VERSION "ODrive v0.5.6 CANSimple - generated by tools/gen_can_dbc.py on 2026-11-18"

NS_ :

BS_:

BU_: HOST ODrive

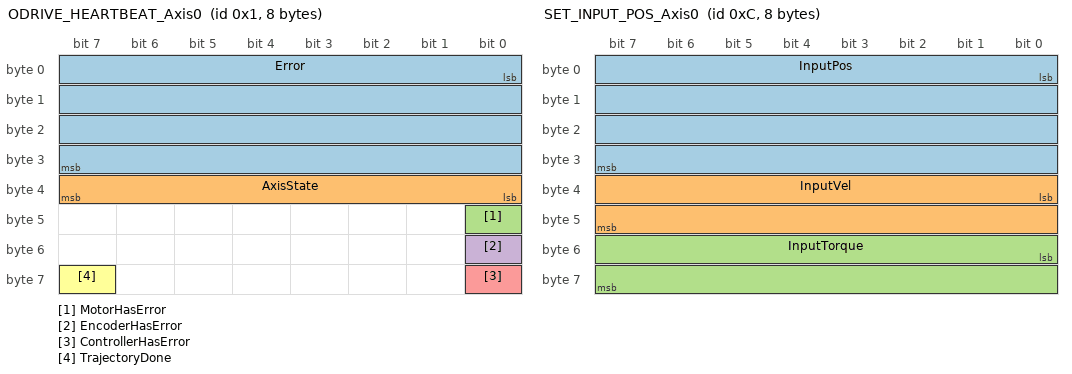
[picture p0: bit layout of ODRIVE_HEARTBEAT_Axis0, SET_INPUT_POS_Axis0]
BO_ 1 ODRIVE_HEARTBEAT_Axis0: 8 ODrive
 SG_ Error : 0|32@1+ (1,0) [0|0] "" HOST
 SG_ AxisState : 32|8@1+ (1,0) [0|0] "" HOST
 SG_ MotorHasError : 40|1@1+ (1,0) [0|0] "" HOST
 SG_ EncoderHasError : 48|1@1+ (1,0) [0|0] "" HOST
 SG_ ControllerHasError : 56|1@1+ (1,0) [0|0] "" HOST
 SG_ TrajectoryDone : 63|1@1+ (1,0) [0|0] "" HOST
CM_ BO_ 1 "Periodic heartbeat (config.can.heartbeat_rate_ms). See CANSimple::send_heartbeat().";
CM_ SG_ 1 Error "Axis::error_ bitfield, see odrive-interface.yaml Axis.Error";
CM_ SG_ 1 AxisState "axis.current_state_";
CM_ SG_ 1 MotorHasError "1 = motor error present";
CM_ SG_ 1 EncoderHasError "1 = encoder error present";
CM_ SG_ 1 ControllerHasError "1 = controller error present";
CM_ SG_ 1 TrajectoryDone "1 = trapezoidal trajectory finished";
VAL_ 1 AxisState 0 "UNDEFINED" 1 "IDLE" 2 "STARTUP_SEQUENCE" 3 "FULL_CALIBRATION_SEQUENCE" 4 "MOTOR_CALIBRATION" 6 "ENCODER_INDEX_SEARCH" 7 "ENCODER_OFFSET_CALIBRATION" 8 "CLOSED_LOOP_CONTROL" 9 "LOCKIN_SPIN" 10 "ENCODER_DIR_FIND" 11 "HOMING" 12 "ENCODER_HALL_POLARITY_CALIBRATION" 13 "ENCODER_HALL_PHASE_CALIBRATION" ;

BO_ 2 ODRIVE_ESTOP_Axis0: 0 HOST
CM_ BO_ 2 "Emergency stop: sets Axis::ERROR_ESTOP_REQUESTED. No payload.";

BO_ 3 GET_MOTOR_ERROR_Axis0: 8 ODrive
 SG_ MotorError : 0|64@1+ (1,0) [0|0] "" HOST
CM_ BO_ 3 "Response: motor error bitfield. Trigger: RTR frame or empty frame with same ID.";
CM_ SG_ 3 MotorError "motor.error_ bitfield (64 bit)";

BO_ 4 GET_ENCODER_ERROR_Axis0: 8 ODrive
 SG_ EncoderError : 0|32@1+ (1,0) [0|0] "" HOST
CM_ BO_ 4 "Response: encoder error. Trigger: RTR or empty frame with same ID.";
CM_ SG_ 4 EncoderError "encoder.error_ bitfield";

BO_ 5 GET_SENSORLESS_ERROR_Axis0: 8 ODrive
 SG_ SensorlessError : 0|32@1+ (1,0) [0|0] "" HOST
CM_ BO_ 5 "Response: sensorless estimator error. Trigger: RTR or empty frame with same ID.";
CM_ SG_ 5 SensorlessError "sensorless_estimator.error_ bitfield";

BO_ 6 SET_AXIS_NODE_ID_Axis0: 8 HOST
 SG_ NewNodeId : 0|32@1+ (1,0) [0|0] "" ODrive
CM_ BO_ 6 "Set a new CAN node id (takes effect immediately, not persisted).";
CM_ SG_ 6 NewNodeId "new axis.config_.can.node_id";

BO_ 7 SET_AXIS_REQUESTED_STATE_Axis0: 8 HOST
 SG_ RequestedState : 0|32@1- (1,0) [0|0] "" ODrive
CM_ BO_ 7 "Request a state machine transition (like odrivetool: axis.requested_state = ...).";
CM_ SG_ 7 RequestedState "see AxisState value table";

BO_ 8 SET_AXIS_STARTUP_CONFIG_Axis0: 8 HOST
CM_ BO_ 8 "Not implemented in firmware v0.5.6.";

BO_ 9 GET_ENCODER_ESTIMATES_Axis0: 8 ODrive
 SG_ PosEstimate : 0|32@1+ (1,0) [0|0] "turn" HOST
 SG_ VelEstimate : 32|32@1+ (1,0) [0|0] "turn/s" HOST
CM_ BO_ 9 "Periodic (config.can.encoder_rate_ms) or on request: position/velocity estimate.";
CM_ SG_ 9 PosEstimate "controller pos_estimate IEEE-754 float32, little-endian (decoded natively via SIG_VALTYPE_).";
CM_ SG_ 9 VelEstimate "controller vel_estimate IEEE-754 float32, little-endian (decoded natively via SIG_VALTYPE_).";
SIG_VALTYPE_ 9 PosEstimate : 1;
SIG_VALTYPE_ 9 VelEstimate : 1;

BO_ 10 GET_ENCODER_COUNT_Axis0: 8 ODrive
 SG_ ShadowCount : 0|32@1- (1,0) [0|0] "" HOST
 SG_ CountInCPR : 32|32@1- (1,0) [0|0] "" HOST
CM_ BO_ 10 "Raw encoder counts (on request).";
CM_ SG_ 10 ShadowCount "encoder.shadow_count_ (raw ticks)";
CM_ SG_ 10 CountInCPR "encoder.count_in_cpr_ (raw ticks)";

BO_ 11 SET_CONTROLLER_MODES_Axis0: 8 HOST
 SG_ ControlMode : 0|32@1- (1,0) [0|0] "" ODrive
 SG_ InputMode : 32|32@1- (1,0) [0|0] "" ODrive
CM_ BO_ 11 "Set control mode and input mode (like odrivetool: controller.config.control_mode/input_mode).";
CM_ SG_ 11 ControlMode "see ControlMode value table";
CM_ SG_ 11 InputMode "see InputMode value table";
VAL_ 11 ControlMode 0 "VOLTAGE_CONTROL" 1 "TORQUE_CONTROL" 2 "VELOCITY_CONTROL" 3 "POSITION_CONTROL" ;
VAL_ 11 InputMode 0 "INACTIVE" 1 "PASSTHROUGH" 2 "VEL_RAMP" 3 "POS_FILTER" 4 "MIX_CHANNELS" 5 "TRAP_TRAJ" 6 "TORQUE_RAMP" 7 "MIRROR" 8 "TUNING" ;

BO_ 12 SET_INPUT_POS_Axis0: 8 HOST
 SG_ InputPos : 0|32@1+ (1,0) [0|0] "turn" ODrive
 SG_ InputVel : 32|16@1- (0.001,0) [-32.768|32.767] "turn/s" ODrive
 SG_ InputTorque : 48|16@1- (0.001,0) [-32.768|32.767] "Nm" ODrive
CM_ BO_ 12 "Position setpoint with optional velocity/torque feedforward (packed 16-bit, 0.001 resolution).";
CM_ SG_ 12 InputPos "position setpoint IEEE-754 float32, little-endian (decoded natively via SIG_VALTYPE_).";
CM_ SG_ 12 InputVel "velocity feedforward, int16 scaled by 0.001";
CM_ SG_ 12 InputTorque "torque feedforward, int16 scaled by 0.001";
SIG_VALTYPE_ 12 InputPos : 1;

BO_ 13 SET_INPUT_VEL_Axis0: 8 HOST
 SG_ InputVel : 0|32@1+ (1,0) [0|0] "turn/s" ODrive
 SG_ InputTorque : 32|32@1+ (1,0) [0|0] "Nm" ODrive
CM_ BO_ 13 "Velocity setpoint with torque feedforward.";
CM_ SG_ 13 InputVel "velocity setpoint IEEE-754 float32, little-endian (decoded natively via SIG_VALTYPE_).";
CM_ SG_ 13 InputTorque "torque feedforward IEEE-754 float32, little-endian (decoded natively via SIG_VALTYPE_).";
SIG_VALTYPE_ 13 InputVel : 1;
SIG_VALTYPE_ 13 InputTorque : 1;

BO_ 14 SET_INPUT_TORQUE_Axis0: 8 HOST
 SG_ InputTorque : 0|32@1+ (1,0) [0|0] "Nm" ODrive
CM_ BO_ 14 "Torque setpoint.";
CM_ SG_ 14 InputTorque "torque setpoint IEEE-754 float32, little-endian (decoded natively via SIG_VALTYPE_).";
SIG_VALTYPE_ 14 InputTorque : 1;

BO_ 15 SET_LIMITS_Axis0: 8 HOST
 SG_ VelLimit : 0|32@1+ (1,0) [0|0] "turn/s" ODrive
 SG_ CurrentLim : 32|32@1+ (1,0) [0|0] "A" ODrive
CM_ BO_ 15 "Set velocity limit and current limit at once.";
CM_ SG_ 15 VelLimit "controller.config.vel_limit IEEE-754 float32, little-endian (decoded natively via SIG_VALTYPE_).";
CM_ SG_ 15 CurrentLim "motor.config.current_lim IEEE-754 float32, little-endian (decoded natively via SIG_VALTYPE_).";
SIG_VALTYPE_ 15 VelLimit : 1;
SIG_VALTYPE_ 15 CurrentLim : 1;

BO_ 16 START_ANTICOGGING_Axis0: 0 HOST
CM_ BO_ 16 "Start anticogging calibration. No payload.";

BO_ 17 SET_TRAJ_VEL_LIMIT_Axis0: 8 HOST
 SG_ VelLimit : 0|32@1+ (1,0) [0|0] "turn/s" ODrive
CM_ BO_ 17 "Trapezoidal trajectory velocity limit.";
CM_ SG_ 17 VelLimit "trap_traj.config.vel_limit IEEE-754 float32, little-endian (decoded natively via SIG_VALTYPE_).";
SIG_VALTYPE_ 17 VelLimit : 1;

BO_ 18 SET_TRAJ_ACCEL_LIMITS_Axis0: 8 HOST
 SG_ AccelLimit : 0|32@1+ (1,0) [0|0] "turn/s^2" ODrive
 SG_ DecelLimit : 32|32@1+ (1,0) [0|0] "turn/s^2" ODrive
CM_ BO_ 18 "Trapezoidal trajectory acceleration/deceleration limits.";
CM_ SG_ 18 AccelLimit "trap_traj.config.accel_limit IEEE-754 float32, little-endian (decoded natively via SIG_VALTYPE_).";
CM_ SG_ 18 DecelLimit "trap_traj.config.decel_limit IEEE-754 float32, little-endian (decoded natively via SIG_VALTYPE_).";
SIG_VALTYPE_ 18 AccelLimit : 1;
SIG_VALTYPE_ 18 DecelLimit : 1;

BO_ 19 SET_TRAJ_INERTIA_Axis0: 8 HOST
 SG_ Inertia : 0|32@1+ (1,0) [0|0] "" ODrive
CM_ BO_ 19 "Set inertia for trajectory planning.";
CM_ SG_ 19 Inertia "controller.config.inertia IEEE-754 float32, little-endian (decoded natively via SIG_VALTYPE_).";
SIG_VALTYPE_ 19 Inertia : 1;

BO_ 20 GET_IQ_Axis0: 8 ODrive
 SG_ IqSetpoint : 0|32@1+ (1,0) [0|0] "A" HOST
 SG_ IqMeasured : 32|32@1+ (1,0) [0|0] "A" HOST
CM_ BO_ 20 "Periodic (config.can.iq_rate_ms) or on request: torque current setpoint/measured.";
CM_ SG_ 20 IqSetpoint "current_control.Idq_setpoint_.q IEEE-754 float32, little-endian (decoded natively via SIG_VALTYPE_).";
CM_ SG_ 20 IqMeasured "current_control.Iq_measured_ IEEE-754 float32, little-endian (decoded natively via SIG_VALTYPE_).";
SIG_VALTYPE_ 20 IqSetpoint : 1;
SIG_VALTYPE_ 20 IqMeasured : 1;

BO_ 21 GET_SENSORLESS_ESTIMATES_Axis0: 8 ODrive
 SG_ PosEstimate : 0|32@1+ (1,0) [0|0] "turn" HOST
 SG_ VelEstimate : 32|32@1+ (1,0) [0|0] "turn/s" HOST
CM_ BO_ 21 "Periodic (config.can.sensorless_rate_ms) or on request: sensorless position/velocity.";
CM_ SG_ 21 PosEstimate "sensorless pll_pos_ IEEE-754 float32, little-endian (decoded natively via SIG_VALTYPE_).";
CM_ SG_ 21 VelEstimate "sensorless vel_estimate_ IEEE-754 float32, little-endian (decoded natively via SIG_VALTYPE_).";
SIG_VALTYPE_ 21 PosEstimate : 1;
SIG_VALTYPE_ 21 VelEstimate : 1;

BO_ 22 RESET_ODRIVE_Axis0: 0 HOST
CM_ BO_ 22 "Reboot the ODrive (NVIC_SystemReset). No payload.";

BO_ 23 GET_BUS_VOLTAGE_CURRENT_Axis0: 8 ODrive
 SG_ VbusVoltage : 0|32@1+ (1,0) [0|0] "V" HOST
 SG_ Ibus : 32|32@1+ (1,0) [0|0] "A" HOST
CM_ BO_ 23 "Periodic (config.can.bus_vi_rate_ms) or on request: DC bus voltage/current.";
CM_ SG_ 23 VbusVoltage "vbus_voltage IEEE-754 float32, little-endian (decoded natively via SIG_VALTYPE_).";
CM_ SG_ 23 Ibus "ibus_ IEEE-754 float32, little-endian (decoded natively via SIG_VALTYPE_).";
SIG_VALTYPE_ 23 VbusVoltage : 1;
SIG_VALTYPE_ 23 Ibus : 1;

BO_ 24 CLEAR_ERRORS_Axis0: 0 HOST
CM_ BO_ 24 "Clear all errors (odrv.clear_errors()). No payload.";

BO_ 25 SET_LINEAR_COUNT_Axis0: 8 HOST
 SG_ LinearCount : 0|32@1- (1,0) [0|0] "" ODrive
CM_ BO_ 25 "Set encoder linear count (encoder.set_linear_count).";
CM_ SG_ 25 LinearCount "raw encoder count";

BO_ 26 SET_POS_GAIN_Axis0: 8 HOST
 SG_ PosGain : 0|32@1+ (1,0) [0|0] "count/s/count" ODrive
CM_ BO_ 26 "Position loop gain.";
CM_ SG_ 26 PosGain "controller.config.pos_gain IEEE-754 float32, little-endian (decoded natively via SIG_VALTYPE_).";
SIG_VALTYPE_ 26 PosGain : 1;

BO_ 27 SET_VEL_GAINS_Axis0: 8 HOST
 SG_ VelGain : 0|32@1+ (1,0) [0|0] "" ODrive
 SG_ VelIntegratorGain : 32|32@1+ (1,0) [0|0] "" ODrive
CM_ BO_ 27 "Velocity loop gains (proportional + integrator).";
CM_ SG_ 27 VelGain "controller.config.vel_gain IEEE-754 float32, little-endian (decoded natively via SIG_VALTYPE_).";
CM_ SG_ 27 VelIntegratorGain "controller.config.vel_integrator_gain IEEE-754 float32, little-endian (decoded natively via SIG_VALTYPE_).";
SIG_VALTYPE_ 27 VelGain : 1;
SIG_VALTYPE_ 27 VelIntegratorGain : 1;

BO_ 28 GET_ADC_VOLTAGE_Axis0: 8 HOST
 SG_ Gpio : 0|8@1+ (1,0) [0|0] "" ODrive
CM_ BO_ 28 "Request: GPIO number in byte 0. ODrive replies on the SAME ID with float32 voltage in bytes 0-3 (see CANSimple::get_adc_voltage_callback); DBC cannot express both directions on one ID.";
CM_ SG_ 28 Gpio "GPIO number to sample (request frame)";

BO_ 29 GET_CONTROLLER_ERROR_Axis0: 8 ODrive
 SG_ ControllerError : 0|32@1+ (1,0) [0|0] "" HOST
CM_ BO_ 29 "Response: controller error. Trigger: RTR or empty frame with same ID.";
CM_ SG_ 29 ControllerError "controller.error_ bitfield";

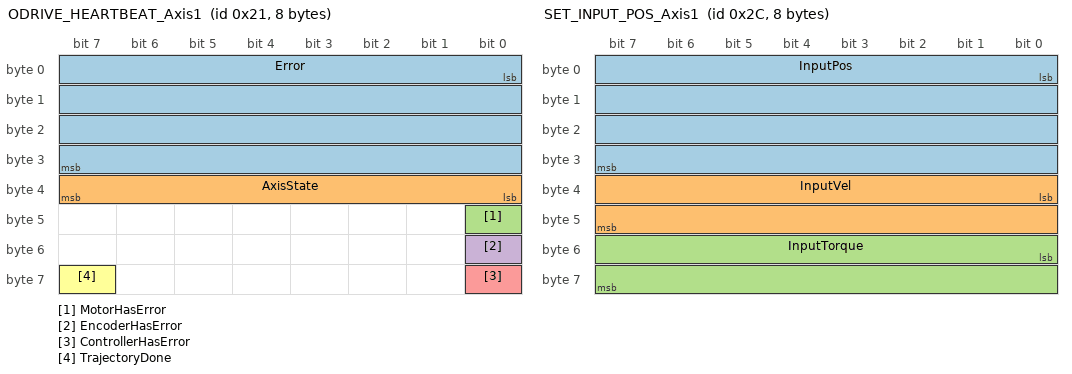
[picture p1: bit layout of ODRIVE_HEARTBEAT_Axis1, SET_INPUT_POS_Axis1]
BO_ 33 ODRIVE_HEARTBEAT_Axis1: 8 ODrive
 SG_ Error : 0|32@1+ (1,0) [0|0] "" HOST
 SG_ AxisState : 32|8@1+ (1,0) [0|0] "" HOST
 SG_ MotorHasError : 40|1@1+ (1,0) [0|0] "" HOST
 SG_ EncoderHasError : 48|1@1+ (1,0) [0|0] "" HOST
 SG_ ControllerHasError : 56|1@1+ (1,0) [0|0] "" HOST
 SG_ TrajectoryDone : 63|1@1+ (1,0) [0|0] "" HOST
CM_ BO_ 33 "Periodic heartbeat (config.can.heartbeat_rate_ms). See CANSimple::send_heartbeat().";
CM_ SG_ 33 Error "Axis::error_ bitfield, see odrive-interface.yaml Axis.Error";
CM_ SG_ 33 AxisState "axis.current_state_";
CM_ SG_ 33 MotorHasError "1 = motor error present";
CM_ SG_ 33 EncoderHasError "1 = encoder error present";
CM_ SG_ 33 ControllerHasError "1 = controller error present";
CM_ SG_ 33 TrajectoryDone "1 = trapezoidal trajectory finished";
VAL_ 33 AxisState 0 "UNDEFINED" 1 "IDLE" 2 "STARTUP_SEQUENCE" 3 "FULL_CALIBRATION_SEQUENCE" 4 "MOTOR_CALIBRATION" 6 "ENCODER_INDEX_SEARCH" 7 "ENCODER_OFFSET_CALIBRATION" 8 "CLOSED_LOOP_CONTROL" 9 "LOCKIN_SPIN" 10 "ENCODER_DIR_FIND" 11 "HOMING" 12 "ENCODER_HALL_POLARITY_CALIBRATION" 13 "ENCODER_HALL_PHASE_CALIBRATION" ;

BO_ 34 ODRIVE_ESTOP_Axis1: 0 HOST
CM_ BO_ 34 "Emergency stop: sets Axis::ERROR_ESTOP_REQUESTED. No payload.";

BO_ 35 GET_MOTOR_ERROR_Axis1: 8 ODrive
 SG_ MotorError : 0|64@1+ (1,0) [0|0] "" HOST
CM_ BO_ 35 "Response: motor error bitfield. Trigger: RTR frame or empty frame with same ID.";
CM_ SG_ 35 MotorError "motor.error_ bitfield (64 bit)";

BO_ 36 GET_ENCODER_ERROR_Axis1: 8 ODrive
 SG_ EncoderError : 0|32@1+ (1,0) [0|0] "" HOST
CM_ BO_ 36 "Response: encoder error. Trigger: RTR or empty frame with same ID.";
CM_ SG_ 36 EncoderError "encoder.error_ bitfield";

BO_ 37 GET_SENSORLESS_ERROR_Axis1: 8 ODrive
 SG_ SensorlessError : 0|32@1+ (1,0) [0|0] "" HOST
CM_ BO_ 37 "Response: sensorless estimator error. Trigger: RTR or empty frame with same ID.";
CM_ SG_ 37 SensorlessError "sensorless_estimator.error_ bitfield";

BO_ 38 SET_AXIS_NODE_ID_Axis1: 8 HOST
 SG_ NewNodeId : 0|32@1+ (1,0) [0|0] "" ODrive
CM_ BO_ 38 "Set a new CAN node id (takes effect immediately, not persisted).";
CM_ SG_ 38 NewNodeId "new axis.config_.can.node_id";

BO_ 39 SET_AXIS_REQUESTED_STATE_Axis1: 8 HOST
 SG_ RequestedState : 0|32@1- (1,0) [0|0] "" ODrive
CM_ BO_ 39 "Request a state machine transition (like odrivetool: axis.requested_state = ...).";
CM_ SG_ 39 RequestedState "see AxisState value table";

BO_ 40 SET_AXIS_STARTUP_CONFIG_Axis1: 8 HOST
CM_ BO_ 40 "Not implemented in firmware v0.5.6.";

BO_ 41 GET_ENCODER_ESTIMATES_Axis1: 8 ODrive
 SG_ PosEstimate : 0|32@1+ (1,0) [0|0] "turn" HOST
 SG_ VelEstimate : 32|32@1+ (1,0) [0|0] "turn/s" HOST
CM_ BO_ 41 "Periodic (config.can.encoder_rate_ms) or on request: position/velocity estimate.";
CM_ SG_ 41 PosEstimate "controller pos_estimate IEEE-754 float32, little-endian (decoded natively via SIG_VALTYPE_).";
CM_ SG_ 41 VelEstimate "controller vel_estimate IEEE-754 float32, little-endian (decoded natively via SIG_VALTYPE_).";
SIG_VALTYPE_ 41 PosEstimate : 1;
SIG_VALTYPE_ 41 VelEstimate : 1;

BO_ 42 GET_ENCODER_COUNT_Axis1: 8 ODrive
 SG_ ShadowCount : 0|32@1- (1,0) [0|0] "" HOST
 SG_ CountInCPR : 32|32@1- (1,0) [0|0] "" HOST
CM_ BO_ 42 "Raw encoder counts (on request).";
CM_ SG_ 42 ShadowCount "encoder.shadow_count_ (raw ticks)";
CM_ SG_ 42 CountInCPR "encoder.count_in_cpr_ (raw ticks)";

BO_ 43 SET_CONTROLLER_MODES_Axis1: 8 HOST
 SG_ ControlMode : 0|32@1- (1,0) [0|0] "" ODrive
 SG_ InputMode : 32|32@1- (1,0) [0|0] "" ODrive
CM_ BO_ 43 "Set control mode and input mode (like odrivetool: controller.config.control_mode/input_mode).";
CM_ SG_ 43 ControlMode "see ControlMode value table";
CM_ SG_ 43 InputMode "see InputMode value table";
VAL_ 43 ControlMode 0 "VOLTAGE_CONTROL" 1 "TORQUE_CONTROL" 2 "VELOCITY_CONTROL" 3 "POSITION_CONTROL" ;
VAL_ 43 InputMode 0 "INACTIVE" 1 "PASSTHROUGH" 2 "VEL_RAMP" 3 "POS_FILTER" 4 "MIX_CHANNELS" 5 "TRAP_TRAJ" 6 "TORQUE_RAMP" 7 "MIRROR" 8 "TUNING" ;

BO_ 44 SET_INPUT_POS_Axis1: 8 HOST
 SG_ InputPos : 0|32@1+ (1,0) [0|0] "turn" ODrive
 SG_ InputVel : 32|16@1- (0.001,0) [-32.768|32.767] "turn/s" ODrive
 SG_ InputTorque : 48|16@1- (0.001,0) [-32.768|32.767] "Nm" ODrive
CM_ BO_ 44 "Position setpoint with optional velocity/torque feedforward (packed 16-bit, 0.001 resolution).";
CM_ SG_ 44 InputPos "position setpoint IEEE-754 float32, little-endian (decoded natively via SIG_VALTYPE_).";
CM_ SG_ 44 InputVel "velocity feedforward, int16 scaled by 0.001";
CM_ SG_ 44 InputTorque "torque feedforward, int16 scaled by 0.001";
SIG_VALTYPE_ 44 InputPos : 1;

BO_ 45 SET_INPUT_VEL_Axis1: 8 HOST
 SG_ InputVel : 0|32@1+ (1,0) [0|0] "turn/s" ODrive
 SG_ InputTorque : 32|32@1+ (1,0) [0|0] "Nm" ODrive
CM_ BO_ 45 "Velocity setpoint with torque feedforward.";
CM_ SG_ 45 InputVel "velocity setpoint IEEE-754 float32, little-endian (decoded natively via SIG_VALTYPE_).";
CM_ SG_ 45 InputTorque "torque feedforward IEEE-754 float32, little-endian (decoded natively via SIG_VALTYPE_).";
SIG_VALTYPE_ 45 InputVel : 1;
SIG_VALTYPE_ 45 InputTorque : 1;

BO_ 46 SET_INPUT_TORQUE_Axis1: 8 HOST
 SG_ InputTorque : 0|32@1+ (1,0) [0|0] "Nm" ODrive
CM_ BO_ 46 "Torque setpoint.";
CM_ SG_ 46 InputTorque "torque setpoint IEEE-754 float32, little-endian (decoded natively via SIG_VALTYPE_).";
SIG_VALTYPE_ 46 InputTorque : 1;

BO_ 47 SET_LIMITS_Axis1: 8 HOST
 SG_ VelLimit : 0|32@1+ (1,0) [0|0] "turn/s" ODrive
 SG_ CurrentLim : 32|32@1+ (1,0) [0|0] "A" ODrive
CM_ BO_ 47 "Set velocity limit and current limit at once.";
CM_ SG_ 47 VelLimit "controller.config.vel_limit IEEE-754 float32, little-endian (decoded natively via SIG_VALTYPE_).";
CM_ SG_ 47 CurrentLim "motor.config.current_lim IEEE-754 float32, little-endian (decoded natively via SIG_VALTYPE_).";
SIG_VALTYPE_ 47 VelLimit : 1;
SIG_VALTYPE_ 47 CurrentLim : 1;

BO_ 48 START_ANTICOGGING_Axis1: 0 HOST
CM_ BO_ 48 "Start anticogging calibration. No payload.";

BO_ 49 SET_TRAJ_VEL_LIMIT_Axis1: 8 HOST
 SG_ VelLimit : 0|32@1+ (1,0) [0|0] "turn/s" ODrive
CM_ BO_ 49 "Trapezoidal trajectory velocity limit.";
CM_ SG_ 49 VelLimit "trap_traj.config.vel_limit IEEE-754 float32, little-endian (decoded natively via SIG_VALTYPE_).";
SIG_VALTYPE_ 49 VelLimit : 1;

BO_ 50 SET_TRAJ_ACCEL_LIMITS_Axis1: 8 HOST
 SG_ AccelLimit : 0|32@1+ (1,0) [0|0] "turn/s^2" ODrive
 SG_ DecelLimit : 32|32@1+ (1,0) [0|0] "turn/s^2" ODrive
CM_ BO_ 50 "Trapezoidal trajectory acceleration/deceleration limits.";
CM_ SG_ 50 AccelLimit "trap_traj.config.accel_limit IEEE-754 float32, little-endian (decoded natively via SIG_VALTYPE_).";
CM_ SG_ 50 DecelLimit "trap_traj.config.decel_limit IEEE-754 float32, little-endian (decoded natively via SIG_VALTYPE_).";
SIG_VALTYPE_ 50 AccelLimit : 1;
SIG_VALTYPE_ 50 DecelLimit : 1;

BO_ 51 SET_TRAJ_INERTIA_Axis1: 8 HOST
 SG_ Inertia : 0|32@1+ (1,0) [0|0] "" ODrive
CM_ BO_ 51 "Set inertia for trajectory planning.";
CM_ SG_ 51 Inertia "controller.config.inertia IEEE-754 float32, little-endian (decoded natively via SIG_VALTYPE_).";
SIG_VALTYPE_ 51 Inertia : 1;

BO_ 52 GET_IQ_Axis1: 8 ODrive
 SG_ IqSetpoint : 0|32@1+ (1,0) [0|0] "A" HOST
 SG_ IqMeasured : 32|32@1+ (1,0) [0|0] "A" HOST
CM_ BO_ 52 "Periodic (config.can.iq_rate_ms) or on request: torque current setpoint/measured.";
CM_ SG_ 52 IqSetpoint "current_control.Idq_setpoint_.q IEEE-754 float32, little-endian (decoded natively via SIG_VALTYPE_).";
CM_ SG_ 52 IqMeasured "current_control.Iq_measured_ IEEE-754 float32, little-endian (decoded natively via SIG_VALTYPE_).";
SIG_VALTYPE_ 52 IqSetpoint : 1;
SIG_VALTYPE_ 52 IqMeasured : 1;

BO_ 53 GET_SENSORLESS_ESTIMATES_Axis1: 8 ODrive
 SG_ PosEstimate : 0|32@1+ (1,0) [0|0] "turn" HOST
 SG_ VelEstimate : 32|32@1+ (1,0) [0|0] "turn/s" HOST
CM_ BO_ 53 "Periodic (config.can.sensorless_rate_ms) or on request: sensorless position/velocity.";
CM_ SG_ 53 PosEstimate "sensorless pll_pos_ IEEE-754 float32, little-endian (decoded natively via SIG_VALTYPE_).";
CM_ SG_ 53 VelEstimate "sensorless vel_estimate_ IEEE-754 float32, little-endian (decoded natively via SIG_VALTYPE_).";
SIG_VALTYPE_ 53 PosEstimate : 1;
SIG_VALTYPE_ 53 VelEstimate : 1;

BO_ 54 RESET_ODRIVE_Axis1: 0 HOST
CM_ BO_ 54 "Reboot the ODrive (NVIC_SystemReset). No payload.";

BO_ 55 GET_BUS_VOLTAGE_CURRENT_Axis1: 8 ODrive
 SG_ VbusVoltage : 0|32@1+ (1,0) [0|0] "V" HOST
 SG_ Ibus : 32|32@1+ (1,0) [0|0] "A" HOST
CM_ BO_ 55 "Periodic (config.can.bus_vi_rate_ms) or on request: DC bus voltage/current.";
CM_ SG_ 55 VbusVoltage "vbus_voltage IEEE-754 float32, little-endian (decoded natively via SIG_VALTYPE_).";
CM_ SG_ 55 Ibus "ibus_ IEEE-754 float32, little-endian (decoded natively via SIG_VALTYPE_).";
SIG_VALTYPE_ 55 VbusVoltage : 1;
SIG_VALTYPE_ 55 Ibus : 1;

BO_ 56 CLEAR_ERRORS_Axis1: 0 HOST
CM_ BO_ 56 "Clear all errors (odrv.clear_errors()). No payload.";

BO_ 57 SET_LINEAR_COUNT_Axis1: 8 HOST
 SG_ LinearCount : 0|32@1- (1,0) [0|0] "" ODrive
CM_ BO_ 57 "Set encoder linear count (encoder.set_linear_count).";
CM_ SG_ 57 LinearCount "raw encoder count";

BO_ 58 SET_POS_GAIN_Axis1: 8 HOST
 SG_ PosGain : 0|32@1+ (1,0) [0|0] "count/s/count" ODrive
CM_ BO_ 58 "Position loop gain.";
CM_ SG_ 58 PosGain "controller.config.pos_gain IEEE-754 float32, little-endian (decoded natively via SIG_VALTYPE_).";
SIG_VALTYPE_ 58 PosGain : 1;

BO_ 59 SET_VEL_GAINS_Axis1: 8 HOST
 SG_ VelGain : 0|32@1+ (1,0) [0|0] "" ODrive
 SG_ VelIntegratorGain : 32|32@1+ (1,0) [0|0] "" ODrive
CM_ BO_ 59 "Velocity loop gains (proportional + integrator).";
CM_ SG_ 59 VelGain "controller.config.vel_gain IEEE-754 float32, little-endian (decoded natively via SIG_VALTYPE_).";
CM_ SG_ 59 VelIntegratorGain "controller.config.vel_integrator_gain IEEE-754 float32, little-endian (decoded natively via SIG_VALTYPE_).";
SIG_VALTYPE_ 59 VelGain : 1;
SIG_VALTYPE_ 59 VelIntegratorGain : 1;

BO_ 60 GET_ADC_VOLTAGE_Axis1: 8 HOST
 SG_ Gpio : 0|8@1+ (1,0) [0|0] "" ODrive
CM_ BO_ 60 "Request: GPIO number in byte 0. ODrive replies on the SAME ID with float32 voltage in bytes 0-3 (see CANSimple::get_adc_voltage_callback); DBC cannot express both directions on one ID.";
CM_ SG_ 60 Gpio "GPIO number to sample (request frame)";

BO_ 61 GET_CONTROLLER_ERROR_Axis1: 8 ODrive
 SG_ ControllerError : 0|32@1+ (1,0) [0|0] "" HOST
CM_ BO_ 61 "Response: controller error. Trigger: RTR or empty frame with same ID.";
CM_ SG_ 61 ControllerError "controller.error_ bitfield";
